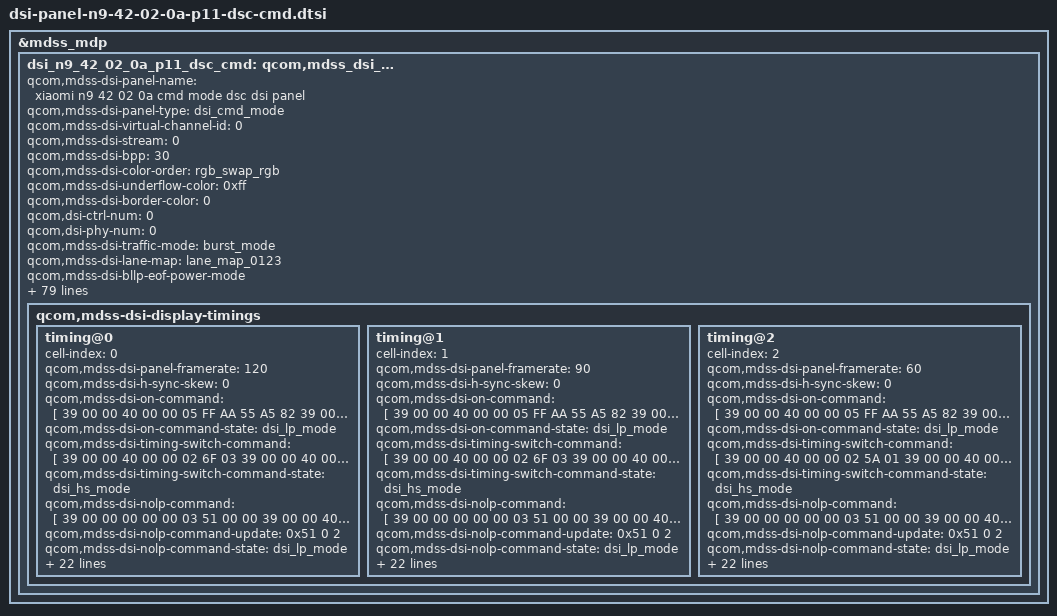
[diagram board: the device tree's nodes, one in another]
&mdss_mdp {
	dsi_n9_42_02_0a_p11_dsc_cmd: qcom,mdss_dsi_n9_42_02_0a_p11_dsc_cmd {
		qcom,mdss-dsi-panel-name = "xiaomi n9 42 02 0a cmd mode dsc dsi panel";
		qcom,mdss-dsi-panel-type = "dsi_cmd_mode";
		qcom,mdss-dsi-virtual-channel-id = <0>;
		qcom,mdss-dsi-stream = <0>;
		qcom,mdss-dsi-bpp = <30>;
		qcom,mdss-dsi-color-order = "rgb_swap_rgb";
		qcom,mdss-dsi-underflow-color = <0xff>;
		qcom,mdss-dsi-border-color = <0>;
		qcom,dsi-ctrl-num = <0>;
		qcom,dsi-phy-num = <0>;
		qcom,mdss-dsi-traffic-mode = "burst_mode";
		qcom,mdss-dsi-lane-map = "lane_map_0123";
		qcom,mdss-dsi-bllp-eof-power-mode;
		qcom,mdss-dsi-bllp-power-mode;
		qcom,mdss-dsi-lane-0-state;
		qcom,mdss-dsi-lane-1-state;
		qcom,mdss-dsi-lane-2-state;
		qcom,mdss-dsi-lane-3-state;
		qcom,mdss-dsi-dma-trigger = "trigger_sw";
		qcom,mdss-dsi-mdp-trigger = "none";
		qcom,mdss-dsi-reset-sequence = <1 1>, <0 1>, <1 10>;
		qcom,mdss-pan-physical-width-dimension = <663>;
		qcom,mdss-pan-physical-height-dimension = <1473>;
		qcom,mdss-dsi-te-pin-select = <1>;
		qcom,mdss-dsi-wr-mem-start = <0x2c>;
		qcom,mdss-dsi-wr-mem-continue = <0x3c>;
		qcom,mdss-dsi-te-dcs-command = <1>;
		qcom,mdss-dsi-te-check-enable;
		qcom,mdss-dsi-te-using-te-pin;
		qcom,mdss-dsi-tx-eot-append;
		qcom,mdss-dsi-lp11-init;
		qcom,mdss-dsi-bl-inverted-dbv;
		qcom,bl-update-flag = "delay_until_first_frame";
		qcom,mdss-dsi-panel-hdr-enabled;
		qcom,mdss-dsi-panel-hdr-color-primaries = <14500 15500 32000
			17000 15500 30000 8000 3000>;
		qcom,mdss-dsi-panel-peak-brightness = <4200000>;
		qcom,mdss-dsi-panel-blackness-level = <3230>;
		qcom,mdss-dsi-dma-schedule-line = <1>;
		qcom,mdss-dsi-dma-schedule-window = <50>;
		/* IRQF_ONESHOT | IRQF_TRIGGER_HEIGH */
		mi,esd-err-irq-gpio = <&tlmm 157 0x2004>;
		//qcom,spr-pack-type = "pentile";
		mi,panel-id = <0x00004E39 0x50420200>;
		//mi,ddic-round-corner-enabled;
		//mi,flat-need-sync-te;
		mi,flatmode-default-on-enabled;
		mi,flatmode-status-check-enabled;
		//mi,mdss-dsi-panel-flatmode-status-offset-command = [
		//	39 00 00 00 00 00 03 F0 AA 11
		//];
		//mi,mdss-dsi-panel-flatmode-status-offset-command-state = "dsi_hs_mode";
		mi,mdss-dsi-panel-flatmode-status-command = [
			06 01 00 01 00 00 01 5F
		];
		mi,mdss-dsi-panel-flatmode-status-command-state = "dsi_hs_mode";
		mi,mdss-dsi-panel-flatmode-status-read-length = <1>;
		mi,mdss-dsi-panel-flatmode-on-status-value = <0x00>;
		mi,mdss-dsi-panel-wp-read-command = [06 01 00 01 00 00 01 A3];
		mi,mdss-dsi-panel-wp-read-command-state = "dsi_hs_mode";
		mi,mdss-dsi-panel-wp-read-length = <8>;
		/* esd-check reg_read */
		//qcom,esd-check-enabled;
		//qcom,esd-aod-check-enabled;
		//mi,mdss-dsi-panel-status-check-interval = <1000>;
		//qcom,mdss-dsi-panel-status-check-mode = "reg_read";
		//mi,mdss-dsi-panel-status-offset-command = [39 00 00 00 00 00 03 FF 5A 82
		//					      39 00 00 00 00 00 02 65 01];
		//qcom,mdss-dsi-panel-status-command = [06 01 00 00 00 00 01 F9];
		//mi,mdss-dsi-panel-status-after-command = [39 00 00 00 00 00 03 FF 5A 00];
		//qcom,mdss-dsi-panel-status-command-state = "dsi_lp_mode";
		//mi,mdss-dsi-panel-status-offset-command-state = "dsi_lp_mode";
		//mi,mdss-dsi-panel-status-after-command-state = "dsi_lp_mode";
		//qcom,mdss-dsi-panel-status-value = <0x08>;
		//qcom,mdss-dsi-panel-status-read-length = <1>;
		mi,panel-on-dimming-delay = <120>;
		mi,max-brightness-clone = <16383>;
		mi,normal-max-brightness-clone = <8191>;
		mi,thermal-dimming-flag;
		mi,mdss-dsi-fac-bl-max-level = <11467>;
		mi,mdss-fac-brightness-max-level = <11467>;
		mi,doze-hbm-dbv-level = <967>;
		mi,doze-lbm-dbv-level = <41>;
		mi,local-hbm-enabled;
		mi,local-hbm-ui-ready-delay-num-frame = <4>;
		mi,local-hbm-update-with-hbm-mode-threshold = <8206>;
		mi,need-fod-animal-in-normal-enabled;

		qcom,mdss-dsi-display-timings {
			timing@0 {
				#include "dsi-panel-n9-42-02-0a-p11-dsc-cmd-common.dtsi"
				cell-index = <0>;
				qcom,mdss-dsi-panel-framerate = <120>;
				qcom,mdss-dsi-h-sync-skew = <0>;
				qcom,mdss-dsi-on-command = [
					/* esd config */
					39 00 00 40 00 00 05 FF AA 55 A5 82
					39 00 00 40 00 00 02 6F 09
					39 00 00 40 00 00 02 F2 FF
					39 00 00 40 00 00 06 F0 55 AA 52 08 01
					39 00 00 40 00 00 02 E5 00
					39 00 00 40 00 00 06 F0 55 AA 52 08 03
					39 00 00 40 00 00 02 6F 04
					39 00 00 40 00 00 02 C7 FD
					39 00 00 40 00 00 05 FF AA 55 A5 80
					39 00 00 40 00 00 02 6F 32
					39 00 00 40 00 00 02 F9 00
					39 00 00 40 00 00 05 FF AA 55 A5 81
					39 00 00 40 00 00 02 6F 02
					39 00 00 40 00 00 02 F9 84
					39 00 00 40 00 00 05 FF AA 55 A5 81
					39 00 00 40 00 00 02 6F 0C
					39 00 00 40 00 00 02 FD 08
					39 00 00 40 00 00 05 FF AA 55 A5 81
					39 00 00 40 00 00 02 6F 10
					39 00 00 40 00 00 02 FB 40
					39 00 00 40 00 00 05 FF AA 55 A5 80
					39 00 00 40 00 00 02 6F 42
					39 00 00 40 00 00 02 F4 00
					39 00 00 40 00 00 02 6F 49
					39 00 00 40 00 00 02 F2 10
					39 00 00 40 00 00 06 F0 55 AA 52 08 07
					39 00 00 40 00 00 02 C0 07
					39 00 00 40 00 00 02 C1 00
					39 00 00 40 00 00 02 C2 00
					39 00 00 40 00 00 02 C3 00
					39 00 00 40 00 00 02 C4 00
					39 00 00 40 00 00 02 C5 00
					39 00 00 40 00 00 02 C6 00
					39 00 00 40 00 00 02 C7 00
					39 00 00 40 00 00 02 C8 00
					39 00 00 40 00 00 02 C9 00
					39 00 00 40 00 00 02 CA 00
					39 00 00 40 00 00 02 CB 00
					39 00 00 40 00 00 06 F0 55 AA 52 08 00
					39 00 00 40 00 00 02 6F 31
					39 00 00 40 00 00 05 C0 32 00 04 50
					39 00 00 40 00 00 02 6F 01
					39 00 00 40 00 00 02 C7 01
					39 00 00 40 00 00 06 F0 55 AA 52 08 01
					39 00 00 40 00 00 02 6F 05
					39 00 00 40 00 00 04 C5 00 0A 0A
					39 00 00 40 00 00 05 FF AA 55 A5 80
					39 00 00 40 00 00 02 6F 31
					39 00 00 40 00 00 03 F8 01 8E
					39 00 00 40 00 00 05 FF AA 55 A5 80
					39 00 00 40 00 00 02 6F 15
					39 00 00 40 00 00 03 F8 01 8D
					39 00 00 40 00 00 02 6F 16
					39 00 00 40 00 00 03 F4 02 74
					39 00 00 40 00 00 05 FF AA 55 A5 81
					39 00 00 40 00 00 02 6F 05
					39 00 00 40 00 00 03 FE 3C 3C
					39 00 00 40 00 00 02 6F 0D
					39 00 00 40 00 00 02 FB 80
					39 00 00 40 00 00 05 FF AA 55 A5 80
					39 00 00 40 00 00 02 6F 0A
					39 00 00 40 00 00 06 F6 70 70 70 70 70
					39 00 00 40 00 00 02 17 30
					39 00 00 40 00 00 05 2A 00 00 04 D3
					39 00 00 40 00 00 05 2B 00 00 0A BD
					39 00 00 40 00 00 02 90 03
					39 00 00 40 00 00 02 6F 01
					39 00 00 40 00 00 02 90 43
					39 00 00 40 00 00 13 91 AB A8 00 32 C2 00 02 35 05 2D 00 08 01 F6 01 C7 10 F0
					39 00 00 40 00 00 02 6F 06
					39 00 00 40 00 00 02 6d 04
					39 00 00 40 00 00 02 2F 00
					39 00 00 40 00 00 02 5F 00
					39 00 00 40 00 00 02 35 00
					39 00 00 40 00 00 02 6F 04
					39 00 00 40 00 00 03 51 3F FF
					39 00 00 40 00 00 02 53 20
					39 00 00 40 00 00 02 26 00
					/* Display On */
					05 00 00 00 78 00 01 11
					05 00 00 00 00 00 01 29
				];
				qcom,mdss-dsi-on-command-state = "dsi_lp_mode";

				qcom,mdss-dsi-timing-switch-command = [
					39 00 00 40 00 00 02 6F 03
					39 00 00 40 00 00 03 35 00 00
					/* Frequency Select 120Hz */
					39 00 00 00 00 00 02 2F 00
				];

				qcom,mdss-dsi-timing-switch-command-state = "dsi_hs_mode";

				qcom,mdss-dsi-nolp-command = [
					39 00 00 00 00 00 03 51 00 00
					/* Aod Mode Off */
					39 00 00 40 00 00 02 2F 00
					39 00 00 00 00 00 02 38 00
				];
				qcom,mdss-dsi-nolp-command-update = <0x51 0 2>;
				qcom,mdss-dsi-nolp-command-state = "dsi_lp_mode";

				mi,mdss-dsi-doze-hbm-nolp-command = [
					39 00 00 00 00 00 03 51 03 C7
					/* Aod Mode Off */
					39 00 00 40 00 00 02 2F 00
					39 00 00 00 00 00 02 38 00
				];
				mi,mdss-dsi-doze-hbm-nolp-command-state = "dsi_hs_mode";

				mi,mdss-dsi-doze-lbm-nolp-command = [
					39 00 00 00 00 00 03 51 00 41
					/* Aod Mode Off */
					39 00 00 40 00 00 02 2F 00
					39 00 00 00 00 00 02 38 00
				];
				mi,mdss-dsi-doze-lbm-nolp-command-state = "dsi_hs_mode";

				mi,mdss-dsi-local-hbm-hlpm-white-1000nit-command = [
					39 00 00 40 00 00 02 8B 10
					39 00 00 40 00 00 06 F0 55 AA 52 08 04
					39 00 00 40 00 00 02 6F 5A
					39 00 00 40 00 00 5B D2 40 40 40 33 18 0F 30 30 30 30 1A 10 30 30 30 30 20 10 30 30 30 30 20 10 40 40 40 40 12 08 40 40 40 33 18 0F 30 30 30 30 1A 10 30 30 30 30 20 10 30 30 30 30 20 10 40 40 40 40 12 08 40 40 40 33 18 0F 30 30 30 30 1A 10 30 30 30 30 20 10 30 30 30 30 20 10 40 40 40 40 12 08
					39 00 00 40 00 00 06 F0 55 AA 52 08 02
					39 00 00 40 00 00 07 D1 00 00 FF FF 00 00
					/*LHBM ON*/
					39 00 00 40 00 00 02 2F 00
					39 00 00 40 00 00 06 F0 55 AA 52 08 00
					39 00 00 40 00 00 02 DF 01
					39 00 00 40 00 00 02 6F 30
					39 00 00 40 00 00 03 DF 00 09
					39 00 00 40 00 00 06 F0 55 AA 52 08 01
					39 00 00 40 00 00 02 6F 2A
					39 00 00 40 00 00 02 B9 00
					39 00 00 40 00 00 0A 88 01 02 64 09 AE 00 00 00 00
					39 00 00 40 00 00 04 87 25 3F F0
					/*AOD OFF*/
					39 00 00 40 00 00 02 2F 00
					39 00 00 00 00 00 02 38 00
					39 00 00 40 00 00 06 F0 55 AA 52 08 07
					39 00 00 40 00 00 02 D1 00
					39 00 00 40 00 00 02 6F 07
					39 00 00 40 00 00 02 D1 00
					39 00 00 40 00 00 02 6F 0E
					39 00 00 40 00 00 02 D1 00
					39 00 00 40 00 00 02 6F 15
					39 00 00 40 00 00 02 D1 00
					39 00 00 40 00 00 02 6F 1C
					39 00 00 40 00 00 02 D1 00
					39 00 00 40 00 00 02 6F 23
					39 00 00 40 00 00 02 D1 00
					39 00 00 40 00 00 02 6F 2A
					39 00 00 40 00 00 02 D1 00
					39 00 00 40 00 00 02 6F 31
					39 00 00 00 00 00 02 D1 00
				];
				mi,mdss-dsi-local-hbm-hlpm-white-1000nit-command-update = <0xD1 5 6>, <0xDF 8 1>, <0xDF 10 2>, <0xB9 13 1>, <0x87 15 3>;
				mi,mdss-dsi-local-hbm-hlpm-white-1000nit-command-state = "dsi_hs_mode";

				mi,mdss-dsi-local-hbm-hlpm-white-110nit-command = [
					39 00 00 40 00 00 02 8B 10
					39 00 00 40 00 00 06 F0 55 AA 52 08 04
					39 00 00 40 00 00 02 6F 5A
					39 00 00 40 00 00 5B D2 40 40 40 33 18 0F 30 30 30 30 1A 10 30 30 30 30 20 10 30 30 30 30 20 10 40 40 40 40 12 08 40 40 40 33 18 0F 30 30 30 30 1A 10 30 30 30 30 20 10 30 30 30 30 20 10 40 40 40 40 12 08 40 40 40 33 18 0F 30 30 30 30 1A 10 30 30 30 30 20 10 30 30 30 30 20 10 40 40 40 40 12 08
					39 00 00 40 00 00 06 F0 55 AA 52 08 02
					39 00 00 40 00 00 07 D1 00 00 FF FF 00 00
					/*LHBM ON*/
					39 00 00 40 00 00 02 2F 00
					39 00 00 40 00 00 06 F0 55 AA 52 08 00
					39 00 00 40 00 00 02 DF 01
					39 00 00 40 00 00 02 6F 30
					39 00 00 40 00 00 03 DF 00 09
					39 00 00 40 00 00 06 F0 55 AA 52 08 01
					39 00 00 40 00 00 02 6F 2A
					39 00 00 40 00 00 02 B9 00
					39 00 00 40 00 00 0A 88 01 02 64 09 AE 00 00 00 00
					39 00 00 40 00 00 04 87 25 3F F0
					/*AOD OFF*/
					39 00 00 40 00 00 02 2F 00
					39 00 00 00 00 00 02 38 00
					39 00 00 40 00 00 06 F0 55 AA 52 08 07
					39 00 00 40 00 00 02 D1 00
					39 00 00 40 00 00 02 6F 07
					39 00 00 40 00 00 02 D1 00
					39 00 00 40 00 00 02 6F 0E
					39 00 00 40 00 00 02 D1 00
					39 00 00 40 00 00 02 6F 15
					39 00 00 40 00 00 02 D1 00
					39 00 00 40 00 00 02 6F 1C
					39 00 00 40 00 00 02 D1 00
					39 00 00 40 00 00 02 6F 23
					39 00 00 40 00 00 02 D1 00
					39 00 00 40 00 00 02 6F 2A
					39 00 00 40 00 00 02 D1 00
					39 00 00 40 00 00 02 6F 31
					39 00 00 00 00 00 02 D1 00
				];
				mi,mdss-dsi-local-hbm-hlpm-white-110nit-command-update = <0xD1 5 6>, <0xDF 8 1>, <0xDF 10 2>, <0xB9 13 1>, <0x87 15 3>;
				mi,mdss-dsi-local-hbm-hlpm-white-110nit-command-state = "dsi_hs_mode";
			};
			timing@1 {
				#include "dsi-panel-n9-42-02-0a-p11-dsc-cmd-common.dtsi"
				cell-index = <1>;
				qcom,mdss-dsi-panel-framerate = <90>;
				qcom,mdss-dsi-h-sync-skew = <0>;
				qcom,mdss-dsi-on-command = [
					/* esd config */
					39 00 00 40 00 00 05 FF AA 55 A5 82
					39 00 00 40 00 00 02 6F 09
					39 00 00 40 00 00 02 F2 FF
					39 00 00 40 00 00 06 F0 55 AA 52 08 01
					39 00 00 40 00 00 02 E5 00
					39 00 00 40 00 00 06 F0 55 AA 52 08 03
					39 00 00 40 00 00 02 6F 04
					39 00 00 40 00 00 02 C7 FD
					39 00 00 40 00 00 05 FF AA 55 A5 80
					39 00 00 40 00 00 02 6F 32
					39 00 00 40 00 00 02 F9 00
					39 00 00 40 00 00 05 FF AA 55 A5 81
					39 00 00 40 00 00 02 6F 02
					39 00 00 40 00 00 02 F9 84
					39 00 00 40 00 00 05 FF AA 55 A5 81
					39 00 00 40 00 00 02 6F 0C
					39 00 00 40 00 00 02 FD 08
					39 00 00 40 00 00 05 FF AA 55 A5 81
					39 00 00 40 00 00 02 6F 10
					39 00 00 40 00 00 02 FB 40
					39 00 00 40 00 00 05 FF AA 55 A5 80
					39 00 00 40 00 00 02 6F 42
					39 00 00 40 00 00 02 F4 00
					39 00 00 40 00 00 02 6F 49
					39 00 00 40 00 00 02 F2 10
					39 00 00 40 00 00 06 F0 55 AA 52 08 07
					39 00 00 40 00 00 02 C0 07
					39 00 00 40 00 00 02 C1 00
					39 00 00 40 00 00 02 C2 00
					39 00 00 40 00 00 02 C3 00
					39 00 00 40 00 00 02 C4 00
					39 00 00 40 00 00 02 C5 00
					39 00 00 40 00 00 02 C6 00
					39 00 00 40 00 00 02 C7 00
					39 00 00 40 00 00 02 C8 00
					39 00 00 40 00 00 02 C9 00
					39 00 00 40 00 00 02 CA 00
					39 00 00 40 00 00 02 CB 00
					39 00 00 40 00 00 06 F0 55 AA 52 08 00
					39 00 00 40 00 00 02 6F 31
					39 00 00 40 00 00 05 C0 32 00 04 50
					39 00 00 40 00 00 02 6F 01
					39 00 00 40 00 00 02 C7 01
					39 00 00 40 00 00 06 F0 55 AA 52 08 01
					39 00 00 40 00 00 02 6F 05
					39 00 00 40 00 00 04 C5 00 0A 0A
					39 00 00 40 00 00 05 FF AA 55 A5 80
					39 00 00 40 00 00 02 6F 31
					39 00 00 40 00 00 03 F8 01 8E
					39 00 00 40 00 00 05 FF AA 55 A5 80
					39 00 00 40 00 00 02 6F 15
					39 00 00 40 00 00 03 F8 01 8D
					39 00 00 40 00 00 02 6F 16
					39 00 00 40 00 00 03 F4 02 74
					39 00 00 40 00 00 05 FF AA 55 A5 81
					39 00 00 40 00 00 02 6F 05
					39 00 00 40 00 00 03 FE 3C 3C
					39 00 00 40 00 00 02 6F 0D
					39 00 00 40 00 00 02 FB 80
					39 00 00 40 00 00 05 FF AA 55 A5 80
					39 00 00 40 00 00 02 6F 0A
					39 00 00 40 00 00 06 F6 70 70 70 70 70
					39 00 00 40 00 00 02 17 30
					39 00 00 40 00 00 05 2A 00 00 04 D3
					39 00 00 40 00 00 05 2B 00 00 0A BD
					39 00 00 40 00 00 02 90 03
					39 00 00 40 00 00 02 6F 01
					39 00 00 40 00 00 02 90 43
					39 00 00 40 00 00 13 91 AB A8 00 32 C2 00 02 35 05 2D 00 08 01 F6 01 C7 10 F0
					39 00 00 40 00 00 02 6F 06
					39 00 00 40 00 00 02 6d 04
					39 00 00 40 00 00 02 2F 01
					39 00 00 40 00 00 02 5F 00
					39 00 00 40 00 00 02 35 00
					39 00 00 40 00 00 02 6F 04
					39 00 00 40 00 00 03 51 3F FF
					39 00 00 40 00 00 02 53 20
					39 00 00 40 00 00 02 26 00
					/* Display On */
					05 00 00 00 78 00 01 11
					05 00 00 00 00 00 01 29
				];
				qcom,mdss-dsi-on-command-state = "dsi_lp_mode";

				qcom,mdss-dsi-timing-switch-command = [
					39 00 00 40 00 00 02 6F 03
					39 00 00 40 00 00 03 35 00 00
					/* Frequency Select 90Hz */
					39 00 00 00 00 00 02 2F 01
				];

				qcom,mdss-dsi-timing-switch-command-state = "dsi_hs_mode";

				qcom,mdss-dsi-nolp-command = [
					39 00 00 00 00 00 03 51 00 00
					/* Aod Mode Off */
					39 00 00 40 00 00 02 2F 01
					39 00 00 00 00 00 02 38 00
				];
				qcom,mdss-dsi-nolp-command-update = <0x51 0 2>;
				qcom,mdss-dsi-nolp-command-state = "dsi_lp_mode";

				mi,mdss-dsi-doze-hbm-nolp-command = [
					39 00 00 00 00 00 03 51 03 C7
					/* Aod Mode Off */
					39 00 00 40 00 00 02 2F 01
					39 00 00 00 00 00 02 38 00
				];
				mi,mdss-dsi-doze-hbm-nolp-command-state = "dsi_hs_mode";

				mi,mdss-dsi-doze-lbm-nolp-command = [
					39 00 00 00 00 00 03 51 00 41
					/* Aod Mode Off */
					39 00 00 40 00 00 02 2F 01
					39 00 00 00 00 00 02 38 00
				];
				mi,mdss-dsi-doze-lbm-nolp-command-state = "dsi_hs_mode";

				mi,mdss-dsi-local-hbm-hlpm-white-1000nit-command = [
					39 00 00 40 00 00 02 8B 10
					39 00 00 40 00 00 06 F0 55 AA 52 08 04
					39 00 00 40 00 00 02 6F 5A
					39 00 00 40 00 00 5B D2 40 40 40 33 18 0F 30 30 30 30 1A 10 30 30 30 30 20 10 30 30 30 30 20 10 40 40 40 40 12 08 40 40 40 33 18 0F 30 30 30 30 1A 10 30 30 30 30 20 10 30 30 30 30 20 10 40 40 40 40 12 08 40 40 40 33 18 0F 30 30 30 30 1A 10 30 30 30 30 20 10 30 30 30 30 20 10 40 40 40 40 12 08
					39 00 00 40 00 00 06 F0 55 AA 52 08 02
					39 00 00 40 00 00 07 D1 00 00 FF FF 00 00
					/*LHBM ON*/
					39 00 00 40 00 00 02 2F 00
					39 00 00 40 00 00 06 F0 55 AA 52 08 00
					39 00 00 40 00 00 02 DF 01
					39 00 00 40 00 00 02 6F 30
					39 00 00 40 00 00 03 DF 00 09
					39 00 00 40 00 00 06 F0 55 AA 52 08 01
					39 00 00 40 00 00 02 6F 2A
					39 00 00 40 00 00 02 B9 00
					39 00 00 40 00 00 0A 88 01 02 64 09 AE 00 00 00 00
					39 00 00 40 00 00 04 87 25 3F F0
					/*AOD OFF*/
					39 00 00 40 00 00 02 2F 01
					39 00 00 00 00 00 02 38 00
					39 00 00 40 00 00 06 F0 55 AA 52 08 07
					39 00 00 40 00 00 02 D1 00
					39 00 00 40 00 00 02 6F 07
					39 00 00 40 00 00 02 D1 00
					39 00 00 40 00 00 02 6F 0E
					39 00 00 40 00 00 02 D1 00
					39 00 00 40 00 00 02 6F 15
					39 00 00 40 00 00 02 D1 00
					39 00 00 40 00 00 02 6F 1C
					39 00 00 40 00 00 02 D1 00
					39 00 00 40 00 00 02 6F 23
					39 00 00 40 00 00 02 D1 00
					39 00 00 40 00 00 02 6F 2A
					39 00 00 40 00 00 02 D1 00
					39 00 00 40 00 00 02 6F 31
					39 00 00 00 00 00 02 D1 00
				];
				mi,mdss-dsi-local-hbm-hlpm-white-1000nit-command-update = <0xD1 5 6>, <0xDF 8 1>, <0xDF 10 2>, <0xB9 13 1>, <0x87 15 3>;
				mi,mdss-dsi-local-hbm-hlpm-white-1000nit-command-state = "dsi_hs_mode";

				mi,mdss-dsi-local-hbm-hlpm-white-110nit-command = [
					39 00 00 40 00 00 02 8B 10
					39 00 00 40 00 00 06 F0 55 AA 52 08 04
					39 00 00 40 00 00 02 6F 5A
					39 00 00 40 00 00 5B D2 40 40 40 33 18 0F 30 30 30 30 1A 10 30 30 30 30 20 10 30 30 30 30 20 10 40 40 40 40 12 08 40 40 40 33 18 0F 30 30 30 30 1A 10 30 30 30 30 20 10 30 30 30 30 20 10 40 40 40 40 12 08 40 40 40 33 18 0F 30 30 30 30 1A 10 30 30 30 30 20 10 30 30 30 30 20 10 40 40 40 40 12 08
					39 00 00 40 00 00 06 F0 55 AA 52 08 02
					39 00 00 40 00 00 07 D1 00 00 FF FF 00 00
					/*LHBM ON*/
					39 00 00 40 00 00 02 2F 00
					39 00 00 40 00 00 06 F0 55 AA 52 08 00
					39 00 00 40 00 00 02 DF 01
					39 00 00 40 00 00 02 6F 30
					39 00 00 40 00 00 03 DF 00 09
					39 00 00 40 00 00 06 F0 55 AA 52 08 01
					39 00 00 40 00 00 02 6F 2A
					39 00 00 40 00 00 02 B9 00
					39 00 00 40 00 00 0A 88 01 02 64 09 AE 00 00 00 00
					39 00 00 40 00 00 04 87 25 3F F0
					/*AOD OFF*/
					39 00 00 40 00 00 02 2F 01
					39 00 00 00 00 00 02 38 00
					39 00 00 40 00 00 06 F0 55 AA 52 08 07
					39 00 00 40 00 00 02 D1 00
					39 00 00 40 00 00 02 6F 07
					39 00 00 40 00 00 02 D1 00
					39 00 00 40 00 00 02 6F 0E
					39 00 00 40 00 00 02 D1 00
					39 00 00 40 00 00 02 6F 15
					39 00 00 40 00 00 02 D1 00
					39 00 00 40 00 00 02 6F 1C
					39 00 00 40 00 00 02 D1 00
					39 00 00 40 00 00 02 6F 23
					39 00 00 40 00 00 02 D1 00
					39 00 00 40 00 00 02 6F 2A
					39 00 00 40 00 00 02 D1 00
					39 00 00 40 00 00 02 6F 31
					39 00 00 00 00 00 02 D1 00
				];
				mi,mdss-dsi-local-hbm-hlpm-white-110nit-command-update = <0xD1 5 6>, <0xDF 8 1>, <0xDF 10 2>, <0xB9 13 1>, <0x87 15 3>;
				mi,mdss-dsi-local-hbm-hlpm-white-110nit-command-state = "dsi_hs_mode";
			};
			timing@2 {
				#include "dsi-panel-n9-42-02-0a-p11-dsc-cmd-common.dtsi"
				cell-index = <2>;
				qcom,mdss-dsi-panel-framerate = <60>;
				qcom,mdss-dsi-h-sync-skew = <0>;
				qcom,mdss-dsi-on-command = [
					/* esd config */
					39 00 00 40 00 00 05 FF AA 55 A5 82
					39 00 00 40 00 00 02 6F 09
					39 00 00 40 00 00 02 F2 FF
					39 00 00 40 00 00 06 F0 55 AA 52 08 01
					39 00 00 40 00 00 02 E5 00
					39 00 00 40 00 00 06 F0 55 AA 52 08 03
					39 00 00 40 00 00 02 6F 04
					39 00 00 40 00 00 02 C7 FD
					39 00 00 40 00 00 05 FF AA 55 A5 80
					39 00 00 40 00 00 02 6F 32
					39 00 00 40 00 00 02 F9 00
					39 00 00 40 00 00 05 FF AA 55 A5 81
					39 00 00 40 00 00 02 6F 02
					39 00 00 40 00 00 02 F9 84
					39 00 00 40 00 00 05 FF AA 55 A5 81
					39 00 00 40 00 00 02 6F 0C
					39 00 00 40 00 00 02 FD 08
					39 00 00 40 00 00 05 FF AA 55 A5 81
					39 00 00 40 00 00 02 6F 10
					39 00 00 40 00 00 02 FB 40
					39 00 00 40 00 00 05 FF AA 55 A5 80
					39 00 00 40 00 00 02 6F 42
					39 00 00 40 00 00 02 F4 00
					39 00 00 40 00 00 02 6F 49
					39 00 00 40 00 00 02 F2 10
					39 00 00 40 00 00 06 F0 55 AA 52 08 07
					39 00 00 40 00 00 02 C0 07
					39 00 00 40 00 00 02 C1 00
					39 00 00 40 00 00 02 C2 00
					39 00 00 40 00 00 02 C3 00
					39 00 00 40 00 00 02 C4 00
					39 00 00 40 00 00 02 C5 00
					39 00 00 40 00 00 02 C6 00
					39 00 00 40 00 00 02 C7 00
					39 00 00 40 00 00 02 C8 00
					39 00 00 40 00 00 02 C9 00
					39 00 00 40 00 00 02 CA 00
					39 00 00 40 00 00 02 CB 00
					39 00 00 40 00 00 06 F0 55 AA 52 08 00
					39 00 00 40 00 00 02 6F 31
					39 00 00 40 00 00 05 C0 32 00 04 50
					39 00 00 40 00 00 02 6F 01
					39 00 00 40 00 00 02 C7 01
					39 00 00 40 00 00 06 F0 55 AA 52 08 01
					39 00 00 40 00 00 02 6F 05
					39 00 00 40 00 00 04 C5 00 0A 0A
					39 00 00 40 00 00 05 FF AA 55 A5 80
					39 00 00 40 00 00 02 6F 31
					39 00 00 40 00 00 03 F8 01 8E
					39 00 00 40 00 00 05 FF AA 55 A5 80
					39 00 00 40 00 00 02 6F 15
					39 00 00 40 00 00 03 F8 01 8D
					39 00 00 40 00 00 02 6F 16
					39 00 00 40 00 00 03 F4 02 74
					39 00 00 40 00 00 05 FF AA 55 A5 81
					39 00 00 40 00 00 02 6F 05
					39 00 00 40 00 00 03 FE 3C 3C
					39 00 00 40 00 00 02 6F 0D
					39 00 00 40 00 00 02 FB 80
					39 00 00 40 00 00 05 FF AA 55 A5 80
					39 00 00 40 00 00 02 6F 0A
					39 00 00 40 00 00 06 F6 70 70 70 70 70
					39 00 00 40 00 00 02 17 30
					39 00 00 40 00 00 05 2A 00 00 04 D3
					39 00 00 40 00 00 05 2B 00 00 0A BD
					39 00 00 40 00 00 02 90 03
					39 00 00 40 00 00 02 6F 01
					39 00 00 40 00 00 02 90 43
					39 00 00 40 00 00 13 91 AB A8 00 32 C2 00 02 35 05 2D 00 08 01 F6 01 C7 10 F0
					39 00 00 40 00 00 02 6F 06
					39 00 00 40 00 00 02 6d 04
					39 00 00 40 00 00 02 5A 01
					39 00 00 40 00 00 02 2F 30
					39 00 00 40 00 00 02 6D 00
					39 00 00 40 00 00 02 5F 00
					39 00 00 40 00 00 02 35 00
					39 00 00 40 00 00 02 6F 04
					39 00 00 40 00 00 03 51 3F FF
					39 00 00 40 00 00 02 53 20
					39 00 00 40 00 00 02 26 00
					39 00 00 40 00 00 02 5A 00
					39 00 00 40 00 00 02 6F 03
					39 00 00 40 00 00 03 35 00 01
					/* Display On */
					05 00 00 00 78 00 01 11
					05 00 00 00 00 00 01 29
				];
				qcom,mdss-dsi-on-command-state = "dsi_lp_mode";

				qcom,mdss-dsi-timing-switch-command = [
					/* Frequency Select 120Hz */
					39 00 00 40 00 00 02 5A 01
					39 00 00 40 00 00 02 2F 30
					39 00 00 40 00 00 02 6D 00
					39 00 00 40 00 00 02 5A 00
					39 00 00 40 00 00 02 6F 03
					39 00 00 00 00 00 03 35 00 01
				];

				qcom,mdss-dsi-timing-switch-command-state = "dsi_hs_mode";

				qcom,mdss-dsi-nolp-command = [
					39 00 00 00 00 00 03 51 00 00
					/* Aod Mode Off */
					39 00 00 40 00 00 02 5A 01
					39 00 00 40 00 00 02 2F 30
					39 00 00 40 00 00 02 6D 00
					39 00 00 40 00 00 02 5A 00
					39 00 00 40 00 00 02 6F 03
					39 00 00 40 00 00 03 35 00 01
					39 00 00 00 00 00 02 38 00
				];
				qcom,mdss-dsi-nolp-command-update = <0x51 0 2>;
				qcom,mdss-dsi-nolp-command-state = "dsi_lp_mode";

				mi,mdss-dsi-doze-hbm-nolp-command = [
					39 00 00 00 00 00 03 51 03 C7
					/* Aod Mode Off */
					39 00 00 40 00 00 02 5A 01
					39 00 00 40 00 00 02 2F 30
					39 00 00 40 00 00 02 6D 00
					39 00 00 40 00 00 02 5A 00
					39 00 00 40 00 00 02 6F 03
					39 00 00 40 00 00 03 35 00 01
					39 00 00 00 00 00 02 38 00
				];
				mi,mdss-dsi-doze-hbm-nolp-command-state = "dsi_hs_mode";

				mi,mdss-dsi-doze-lbm-nolp-command = [
					39 00 00 00 00 00 03 51 00 41
					/* Aod Mode Off */
					39 00 00 40 00 00 02 5A 01
					39 00 00 40 00 00 02 2F 30
					39 00 00 40 00 00 02 6D 00
					39 00 00 40 00 00 02 5A 00
					39 00 00 40 00 00 02 6F 03
					39 00 00 40 00 00 03 35 00 01
					39 00 00 00 00 00 02 38 00
				];
				mi,mdss-dsi-doze-lbm-nolp-command-state = "dsi_hs_mode";

				mi,mdss-dsi-local-hbm-hlpm-white-1000nit-command = [
					39 00 00 40 00 00 02 8B 10
					39 00 00 40 00 00 06 F0 55 AA 52 08 04
					39 00 00 40 00 00 02 6F 5A
					39 00 00 40 00 00 5B D2 40 40 40 33 18 0F 30 30 30 30 1A 10 30 30 30 30 20 10 30 30 30 30 20 10 40 40 40 40 12 08 40 40 40 33 18 0F 30 30 30 30 1A 10 30 30 30 30 20 10 30 30 30 30 20 10 40 40 40 40 12 08 40 40 40 33 18 0F 30 30 30 30 1A 10 30 30 30 30 20 10 30 30 30 30 20 10 40 40 40 40 12 08
					39 00 00 40 00 00 06 F0 55 AA 52 08 02
					39 00 00 40 00 00 07 D1 00 00 FF FF 00 00
					/*LHBM ON*/
					39 00 00 40 00 00 02 2F 00
					39 00 00 40 00 00 06 F0 55 AA 52 08 00
					39 00 00 40 00 00 02 DF 01
					39 00 00 40 00 00 02 6F 30
					39 00 00 40 00 00 03 DF 00 09
					39 00 00 40 00 00 06 F0 55 AA 52 08 01
					39 00 00 40 00 00 02 6F 2A
					39 00 00 40 00 00 02 B9 00
					39 00 00 40 00 00 0A 88 01 02 64 09 AE 00 00 00 00
					39 00 00 40 00 00 04 87 25 3F F0
					/*AOD OFF*/
					39 00 00 40 00 00 02 5A 01
					39 00 00 40 00 00 02 2F 30
					39 00 00 40 00 00 02 6D 00
					39 00 00 40 00 00 02 5A 00
					39 00 00 40 00 00 02 6F 03
					39 00 00 40 00 00 03 35 00 01
					39 00 00 00 00 00 02 38 00
					39 00 00 40 00 00 06 F0 55 AA 52 08 07
					39 00 00 40 00 00 02 D1 00
					39 00 00 40 00 00 02 6F 07
					39 00 00 40 00 00 02 D1 00
					39 00 00 40 00 00 02 6F 0E
					39 00 00 40 00 00 02 D1 00
					39 00 00 40 00 00 02 6F 15
					39 00 00 40 00 00 02 D1 00
					39 00 00 40 00 00 02 6F 1C
					39 00 00 40 00 00 02 D1 00
					39 00 00 40 00 00 02 6F 23
					39 00 00 40 00 00 02 D1 00
					39 00 00 40 00 00 02 6F 2A
					39 00 00 40 00 00 02 D1 00
					39 00 00 40 00 00 02 6F 31
					39 00 00 00 00 00 02 D1 00
				];
				mi,mdss-dsi-local-hbm-hlpm-white-1000nit-command-update = <0xD1 5 6>, <0xDF 8 1>, <0xDF 10 2>, <0xB9 13 1>, <0x87 15 3>;
				mi,mdss-dsi-local-hbm-hlpm-white-1000nit-command-state = "dsi_hs_mode";

				mi,mdss-dsi-local-hbm-hlpm-white-110nit-command = [
					39 00 00 40 00 00 02 8B 10
					39 00 00 40 00 00 06 F0 55 AA 52 08 04
					39 00 00 40 00 00 02 6F 5A
					39 00 00 40 00 00 5B D2 40 40 40 33 18 0F 30 30 30 30 1A 10 30 30 30 30 20 10 30 30 30 30 20 10 40 40 40 40 12 08 40 40 40 33 18 0F 30 30 30 30 1A 10 30 30 30 30 20 10 30 30 30 30 20 10 40 40 40 40 12 08 40 40 40 33 18 0F 30 30 30 30 1A 10 30 30 30 30 20 10 30 30 30 30 20 10 40 40 40 40 12 08
					39 00 00 40 00 00 06 F0 55 AA 52 08 02
					39 00 00 40 00 00 07 D1 00 00 FF FF 00 00
					/*LHBM ON*/
					39 00 00 40 00 00 02 2F 00
					39 00 00 40 00 00 06 F0 55 AA 52 08 00
					39 00 00 40 00 00 02 DF 01
					39 00 00 40 00 00 02 6F 30
					39 00 00 40 00 00 03 DF 00 09
					39 00 00 40 00 00 06 F0 55 AA 52 08 01
					39 00 00 40 00 00 02 6F 2A
					39 00 00 40 00 00 02 B9 00
					39 00 00 40 00 00 0A 88 01 02 64 09 AE 00 00 00 00
					39 00 00 40 00 00 04 87 25 3F F0
					/*AOD OFF*/
					39 00 00 40 00 00 02 5A 01
					39 00 00 40 00 00 02 2F 30
					39 00 00 40 00 00 02 6D 00
					39 00 00 40 00 00 02 5A 00
					39 00 00 40 00 00 02 6F 03
					39 00 00 40 00 00 03 35 00 01
					39 00 00 00 00 00 02 38 00
					39 00 00 40 00 00 06 F0 55 AA 52 08 07
					39 00 00 40 00 00 02 D1 00
					39 00 00 40 00 00 02 6F 07
					39 00 00 40 00 00 02 D1 00
					39 00 00 40 00 00 02 6F 0E
					39 00 00 40 00 00 02 D1 00
					39 00 00 40 00 00 02 6F 15
					39 00 00 40 00 00 02 D1 00
					39 00 00 40 00 00 02 6F 1C
					39 00 00 40 00 00 02 D1 00
					39 00 00 40 00 00 02 6F 23
					39 00 00 40 00 00 02 D1 00
					39 00 00 40 00 00 02 6F 2A
					39 00 00 40 00 00 02 D1 00
					39 00 00 40 00 00 02 6F 31
					39 00 00 00 00 00 02 D1 00
				];
				mi,mdss-dsi-local-hbm-hlpm-white-110nit-command-update = <0xD1 5 6>, <0xDF 8 1>, <0xDF 10 2>, <0xB9 13 1>, <0x87 15 3>;
				mi,mdss-dsi-local-hbm-hlpm-white-110nit-command-state = "dsi_hs_mode";
			};
		};
	};
};
&dsi_n9_42_02_0a_p11_dsc_cmd {
	qcom,panel-supply-entries = <&dsi_panel_pwr_supply_N9>;
	qcom,mdss-dsi-bl-pmic-control-type = "bl_ctrl_dcs";
	qcom,mdss-dsi-bl-min-level = <15>;
	qcom,mdss-dsi-bl-max-level = <16383>;
	qcom,bl-dsc-cmd-state = "dsi_hs_mode";
	qcom,mdss-brightness-max-level = <16383>;
	qcom,mdss-brightness-init-level = <307>;
	qcom,platform-reset-gpio = <&tlmm 2 0>;
	mi,panel-build-id-read-needed;
	mi,panel-build-id-read-length = <1>;
	mi,mdss-dsi-panel-build-id-read-command = [06 01 00 01 00 00 01 DA];
	mi,mdss-dsi-panel-build-id-read-command-state = "dsi_hs_mode";
	mi,disable-ic-dimming-flag;
	qcom,mdss-dsi-panel-vsync-delay;
	qcom,ulps-enabled;
	qcom,dsi-select-clocks = "pll_byte_clk0", "pll_dsi_clk0";
	qcom,mdss-dsi-clk-strength = <0xFF>;
};
